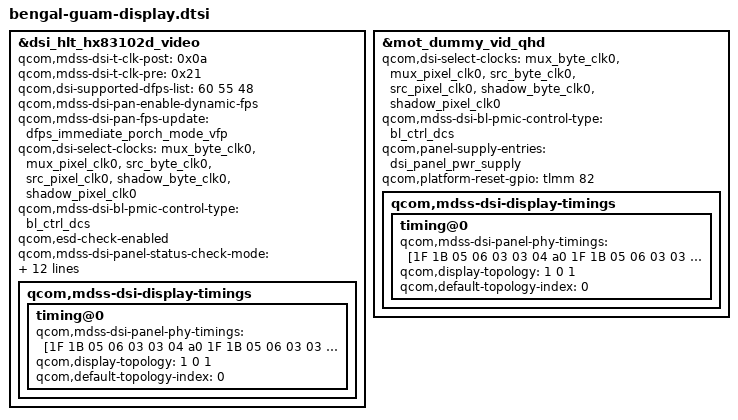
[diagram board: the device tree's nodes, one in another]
#include <dt-bindings/clock/mdss-14nm-pll-clk.h>
#include "bengal-sde-display.dtsi"
#include "dsi-panel-mot-dummy-qhd-video.dtsi"
#include "dsi-panel-moto-hx83102d-hlt-hdplus-video.dtsi"



&dsi_hlt_hx83102d_video {
	qcom,mdss-dsi-t-clk-post = <0x0a>;
	qcom,mdss-dsi-t-clk-pre = <0x21>;
	qcom,dsi-supported-dfps-list = <60 55 48>;
	qcom,mdss-dsi-pan-enable-dynamic-fps;
	qcom,mdss-dsi-pan-fps-update =
		"dfps_immediate_porch_mode_vfp";
	qcom,dsi-select-clocks = "mux_byte_clk0", "mux_pixel_clk0",
				"src_byte_clk0", "src_pixel_clk0",
				"shadow_byte_clk0", "shadow_pixel_clk0";

	qcom,mdss-dsi-bl-pmic-control-type = "bl_ctrl_dcs";
	qcom,esd-check-enabled;
	qcom,mdss-dsi-panel-status-check-mode = "reg_read";
	qcom,mdss-dsi-panel-status-command =[06 01 00 01 00 00 01 09];
	qcom,mdss-dsi-panel-status-command-state = "dsi_lp_mode";
	qcom,mdss-dsi-panel-status-value = <0x80 0x73 0x04>;
	qcom,mdss-dsi-panel-status-read-length = <3>;
	qcom,mdss-dsi-no-panel-on-read-support;

	qcom,panel-supply-entries = <&dsi_panel_pwr_supply>;
	qcom,platform-reset-gpio = <&tlmm 82 0>;

	qcom,mdss-dsi-display-timings {
		timing@0 {
			qcom,mdss-dsi-panel-phy-timings =
				[1F 1B 05 06 03 03 04 a0
				1F 1B 05 06 03 03 04 a0
				1F 1B 05 06 03 03 04 a0
				1F 1B 05 06 03 03 04 a0
				1F 10 04 06 03 03 04 a0];
			qcom,display-topology = <1 0 1>;
			qcom,default-topology-index = <0>;
		};
	};
};

&mot_dummy_vid_qhd {
	qcom,dsi-select-clocks = "mux_byte_clk0", "mux_pixel_clk0",
				"src_byte_clk0", "src_pixel_clk0",
				"shadow_byte_clk0", "shadow_pixel_clk0";

	qcom,mdss-dsi-bl-pmic-control-type = "bl_ctrl_dcs";
	qcom,panel-supply-entries = <&dsi_panel_pwr_supply>;
	qcom,platform-reset-gpio = <&tlmm 82 0>;

	qcom,mdss-dsi-display-timings {
		timing@0 {
			qcom,mdss-dsi-panel-phy-timings =
				[1F 1B 05 06 03 03 04 a0
				1F 1B 05 06 03 03 04 a0
				1F 1B 05 06 03 03 04 a0
				1F 1B 05 06 03 03 04 a0
				1F 10 04 06 03 03 04 a0];
			qcom,display-topology = <1 0 1>;
			qcom,default-topology-index = <0>;
		};
	};
};
